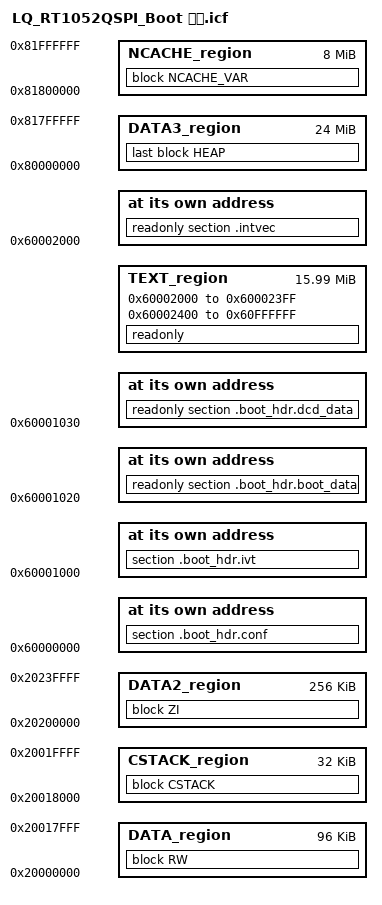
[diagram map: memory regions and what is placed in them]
/*LLLLLLLLLLLLLLLLLLLLLLLLLLLLLLLLLLLLLLLLLLLLLLLLLLLLLLLLLLLLLL
【平    台】龙邱i.MX RT1052核心板-智能车板
【编    写】CHIUSIR
【E-mail  】chiusir@163.com
【软件版本】V1.0，龙邱开源代码，仅供参考，后果自负
【最后更新】2018年2月5日
【相关信息参考下列地址】
【网    站】http://www.lqist.cn
【淘宝店铺】http://shop36265907.taobao.com
------------------------------------------------
【dev.env.】IAR8.20.1及以上版本
【Target 】 i.MX RT1052
【Crystal】 24.000Mhz
【ARM PLL】 1200MHz
【SYS PLL】 528MHz
【USB PLL】 480MHz
================================================
北京龙邱智能科技：从QSPI FLASH启动，SDRAM为32M字节 Flash 16M字节
个人水平有限 注释仅为个人理解 欢迎斧正
QQQQQQQQQQQQQQQQQQQQQQQQQQQQQQQQQQQQQQQQQQQQQQQQQQQQQQQQQQQQQQQ*/
/*一个完整的image 共5个部分组成 Flash Configuration Parameters， IVT， Boot Data， DCD 和用户 image 具体见龙邱RT1052快速入门第七章*/
define exported symbol m_boot_hdr_conf_start = 0x60000000;   /*存放Flash配置信息*/
define symbol m_boot_hdr_ivt_start           = 0x60001000;   /*存放ivt信息*/
define symbol m_boot_hdr_boot_data_start     = 0x60001020;   /*存放boot信息*/
define symbol m_boot_hdr_dcd_data_start      = 0x60001030;   /*存放dcd信息*/

define symbol m_interrupts_start       = 0x60002000;         /*中断向量表开始位置*/
define symbol m_interrupts_end         = 0x600023FF;         /*中断向量表结束位置*/

define symbol m_text_start             = 0x60002400;         /*Flash开始位置*/
define symbol m_text_end               = 0x60FFFFFF;         /*Flash结束位置*/
/*RT1052自带的RAM 默认为 128K的DTCRAM 和 128K的ITCRAM（不需要自己定义位置） 和 256K的OCRAM*/
define symbol m_data_start             = 0x20000000;         /*DTCRAM开始位置*/
define symbol m_data_end               = 0x2001FFFF;         /*DTCRAM结束位置*/

define symbol m_data2_start            = 0x20200000;         /*OCRAM开始位置*/
define symbol m_data2_end              = 0x2023FFFF;         /*OCRAM结束位置*/
/*SDRAM 32M 分成 24M 和 8M  可以自行修改*/
define symbol m_data3_start            = 0x80000000;         /*DATA3  24M*/
define symbol m_data3_end              = 0x817FFFFF;

define symbol m_ncache_start           = 0x81800000;         /*NCACHE 8M*/
define symbol m_ncache_end             = 0x81FFFFFF;

/* Sizes */
if (isdefinedsymbol(__stack_size__)) {
  define symbol __size_cstack__        = __stack_size__;
} else {
  define symbol __size_cstack__        = 0x8000;         /*栈大小*/
}

if (isdefinedsymbol(__heap_size__)) {
  define symbol __size_heap__          = __heap_size__;
} else {
  define symbol __size_heap__          = 0x100000;       /*堆大小*/
}

define exported symbol __VECTOR_TABLE  = m_interrupts_start;   /*中断向量表开始地址 可以从启动文件查看*/
define exported symbol __VECTOR_RAM    = m_interrupts_start;
define exported symbol __RAM_VECTOR_TABLE_SIZE = 0x0;

define memory mem with size = 4G;
define region TEXT_region = mem:[from m_interrupts_start to m_interrupts_end]     /*定义TEXT区域*/
                          | mem:[from m_text_start to m_text_end];
/*定义DATA区域 因为栈也使用的是m_data_end所以要减去栈大小*/
define region DATA_region = mem:[from m_data_start to m_data_end-__size_cstack__];
define region DATA2_region = mem:[from m_data2_start to m_data2_end];             /*定义DATA2区域*/
define region DATA3_region  = mem:[from m_data3_start to m_data3_end];            /*定义DATA3区域*/
define region CSTACK_region = mem:[from m_data_end-__size_cstack__+1 to m_data_end]; /*定义栈区域*/
define region NCACHE_region = mem:[from m_ncache_start to m_ncache_end];             /*定义NCACHE区域*/

/*定义地址块 */
define block CSTACK    with alignment = 8, size = __size_cstack__   { };
define block HEAP      with alignment = 8, size = __size_heap__     { };
define block RW        { first readwrite, section m_usb_dma_init_data };
define block ZI         with alignment = 32  { first zi, section m_usb_dma_noninit_data };
define block NCACHE_VAR with size = 0x800000 , alignment = 0x100000  { section NonCacheable , section NonCacheable.init };

initialize by copy { readwrite, section .textrw };   /*启动时初始化所有属性为readwrite 和 section .textrw 的sections*/
do not initialize  { section .noinit };              /*规定在程序启动时不需要初始化 section .noinit*/

/* 把.intvec 放置 m_interrupts_start 地址处  */
place at address mem: m_interrupts_start    { readonly section .intvec };  

place at address mem:m_boot_hdr_conf_start { section .boot_hdr.conf };
place at address mem:m_boot_hdr_ivt_start { section .boot_hdr.ivt };
place at address mem:m_boot_hdr_boot_data_start { readonly section .boot_hdr.boot_data };
place at address mem:m_boot_hdr_dcd_data_start { readonly section .boot_hdr.dcd_data };

keep{ section .boot_hdr.conf, section .boot_hdr.ivt, section .boot_hdr.boot_data, section .boot_hdr.dcd_data };

place in TEXT_region                        { readonly };                /*指令和常量存放区域*/
place in DATA_region                        { block RW };                /*已初始化变量存放区域*/
place in DATA2_region                        { block ZI };                /*未初始化变量存放区域*/ 
place in DATA3_region                       { last block HEAP };         /*堆区域*/
place in CSTACK_region                      { block CSTACK };            /*栈区域*/ 
place in NCACHE_region                      { block NCACHE_VAR };        /*存放NCACHE数据的区域*/

